# HDSC_HC32M423 register map
Vendor: HDSC Co.,Ltd.; Series: ARMCM4; File version: 1.0
CPU: CM4 r0p1, little endian, MPU, FPU, 4 interrupt priority bits
Registers are 32-bit, read-write, reset 0x0 unless marked. A register's access mark holds for its fields unless they carry their own. Offsets are from the block's base; [hi:lo] are bit positions; {n}, {i} and the like mark numbered series; 'fields as' and 'values as' point back to an identical list.

## GPIO
Base 0x40053800
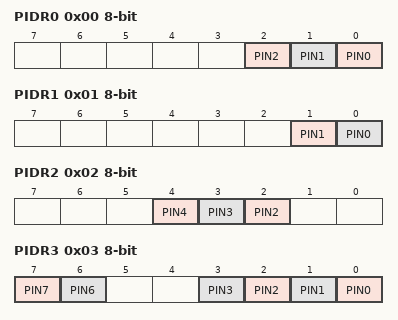
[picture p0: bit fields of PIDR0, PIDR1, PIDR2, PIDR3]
0x00 PIDR0 8-bit ro
  [2] PIN2, [1] PIN1, [0] PIN0
0x01 PIDR1 8-bit ro
  [1] PIN1, [0] PIN0
0x02 PIDR2 8-bit ro
  [4] PIN4, [3] PIN3, [2] PIN2
0x03 PIDR3 8-bit ro
  [7] PIN7, [6] PIN6, [n] PIN{n} (n=0..3)
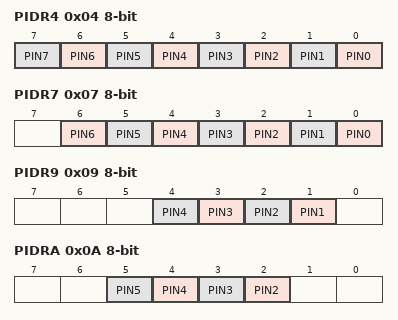
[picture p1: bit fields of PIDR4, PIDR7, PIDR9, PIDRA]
0x04 PIDR4 8-bit ro
  [n] PIN{n} (n=0..7)
0x05 PIDR5 8-bit ro
  [0] PIN0
0x07 PIDR7 8-bit ro
  [n] PIN{n} (n=0..6)
0x09 PIDR9 8-bit ro
  [n] PIN{n} (n=1..4)
0x0A PIDRA 8-bit ro
  [n] PIN{n} (n=2..5)
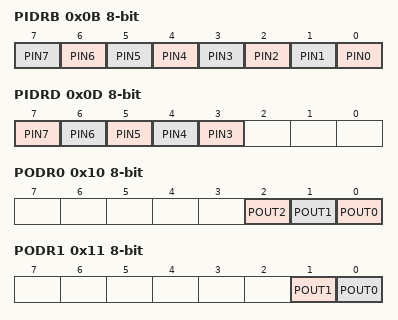
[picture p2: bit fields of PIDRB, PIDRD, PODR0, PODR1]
0x0B PIDRB 8-bit ro
  [n] PIN{n} (n=0..7)
0x0D PIDRD 8-bit ro
  [n] PIN{n} (n=3..7)
0x0E PIDRE 8-bit ro
  [2] PIN2
0x10 PODR0 8-bit
  [2] POUT2, [1] POUT1, [0] POUT0
0x11 PODR1 8-bit
  [1] POUT1, [0] POUT0
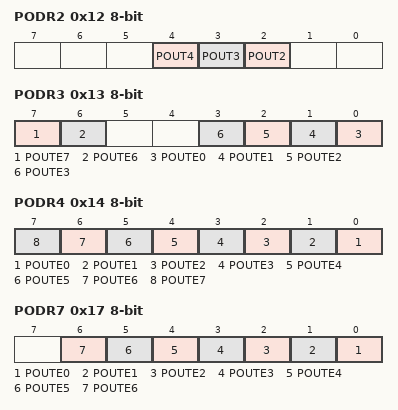
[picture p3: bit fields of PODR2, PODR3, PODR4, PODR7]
0x12 PODR2 8-bit
  [4] POUT4, [3] POUT3, [2] POUT2
0x13 PODR3 8-bit
  [7] POUTE7, [6] POUTE6, [n] POUTE{n} (n=0..3)
0x14 PODR4 8-bit
  [n] POUTE{n} (n=0..7)
0x15 PODR5 8-bit
  [0] POUTE0
0x17 PODR7 8-bit
  [n] POUTE{n} (n=0..6)
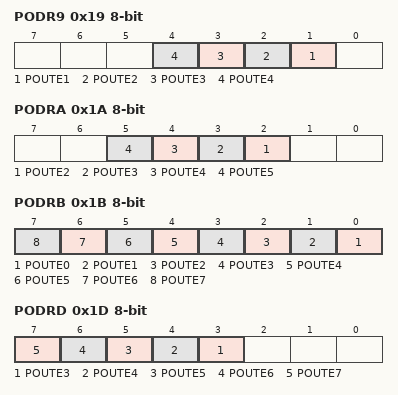
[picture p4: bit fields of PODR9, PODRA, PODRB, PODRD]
0x19 PODR9 8-bit
  [n] POUTE{n} (n=1..4)
0x1A PODRA 8-bit
  [n] POUTE{n} (n=2..5)
0x1B PODRB 8-bit
  [n] POUTE{n} (n=0..7)
0x1D PODRD 8-bit
  [n] POUTE{n} (n=3..7)
0x1E PODRE 8-bit
  [2] POUTE2
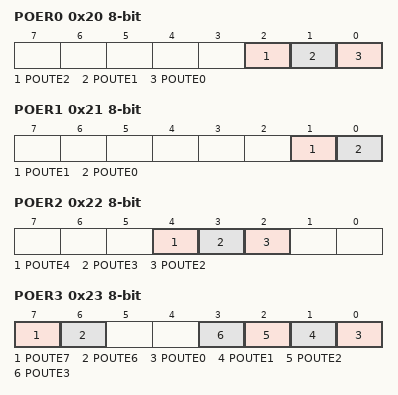
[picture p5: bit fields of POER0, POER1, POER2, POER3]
0x20 POER0 8-bit
  [2] POUTE2, [1] POUTE1, [0] POUTE0
0x21 POER1 8-bit
  [1] POUTE1, [0] POUTE0
0x22 POER2 8-bit
  [4] POUTE4, [3] POUTE3, [2] POUTE2
0x23 POER3 8-bit
  [7] POUTE7, [6] POUTE6, [n] POUTE{n} (n=0..3)
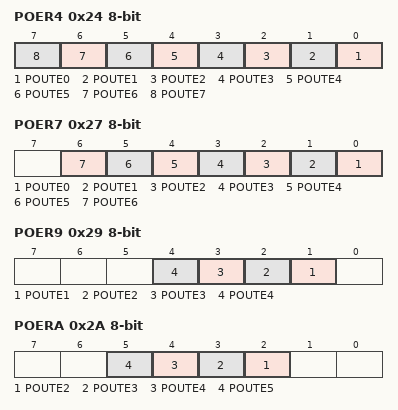
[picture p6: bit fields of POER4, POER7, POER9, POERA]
0x24 POER4 8-bit
  [n] POUTE{n} (n=0..7)
0x25 POER5 8-bit
  [0] POUTE0
0x27 POER7 8-bit
  [n] POUTE{n} (n=0..6)
0x29 POER9 8-bit
  [n] POUTE{n} (n=1..4)
0x2A POERA 8-bit
  [n] POUTE{n} (n=2..5)
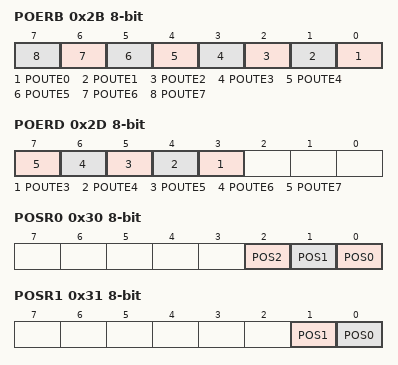
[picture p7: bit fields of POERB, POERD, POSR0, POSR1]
0x2B POERB 8-bit
  [n] POUTE{n} (n=0..7)
0x2D POERD 8-bit
  [n] POUTE{n} (n=3..7)
0x2E POERE 8-bit
  [2] POUTE2
0x30 POSR0 8-bit wo
  [2] POS2, [1] POS1, [0] POS0
0x31 POSR1 8-bit wo
  [1] POS1, [0] POS0
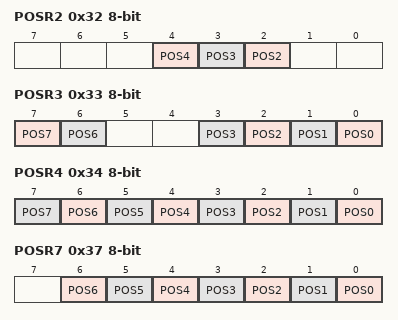
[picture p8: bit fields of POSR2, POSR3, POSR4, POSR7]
0x32 POSR2 8-bit wo
  [4] POS4, [3] POS3, [2] POS2
0x33 POSR3 8-bit wo
  [7] POS7, [6] POS6, [n] POS{n} (n=0..3)
0x34 POSR4 8-bit wo
  [n] POS{n} (n=0..7)
0x35 POSR5 8-bit wo
  [0] POS0
0x37 POSR7 8-bit wo
  [n] POS{n} (n=0..6)
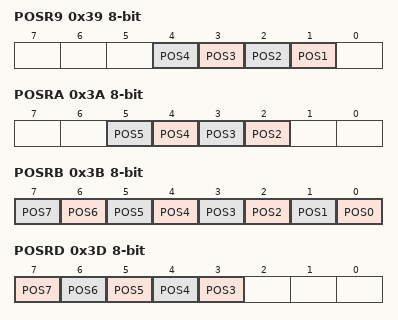
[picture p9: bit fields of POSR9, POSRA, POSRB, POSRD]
0x39 POSR9 8-bit wo
  [n] POS{n} (n=1..4)
0x3A POSRA 8-bit wo
  [n] POS{n} (n=2..5)
0x3B POSRB 8-bit wo
  [n] POS{n} (n=0..7)
0x3D POSRD 8-bit wo
  [n] POS{n} (n=3..7)
0x3E POSRE 8-bit wo
  [2] POS2
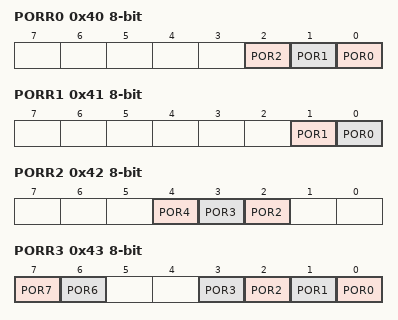
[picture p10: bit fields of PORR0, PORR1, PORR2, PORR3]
0x40 PORR0 8-bit wo
  [2] POR2, [1] POR1, [0] POR0
0x41 PORR1 8-bit wo
  [1] POR1, [0] POR0
0x42 PORR2 8-bit wo
  [4] POR4, [3] POR3, [2] POR2
0x43 PORR3 8-bit wo
  [7] POR7, [6] POR6, [n] POR{n} (n=0..3)
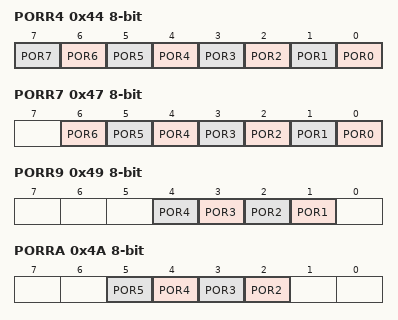
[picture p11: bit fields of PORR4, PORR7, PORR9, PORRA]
0x44 PORR4 8-bit wo
  [n] POR{n} (n=0..7)
0x45 PORR5 8-bit wo
  [0] POR0
0x47 PORR7 8-bit wo
  [n] POR{n} (n=0..6)
0x49 PORR9 8-bit wo
  [n] POR{n} (n=1..4)
0x4A PORRA 8-bit wo
  [n] POR{n} (n=2..5)
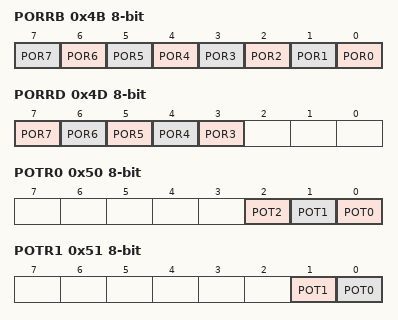
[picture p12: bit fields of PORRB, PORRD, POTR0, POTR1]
0x4B PORRB 8-bit wo
  [n] POR{n} (n=0..7)
0x4D PORRD 8-bit wo
  [n] POR{n} (n=3..7)
0x4E PORRE 8-bit wo
  [2] POR2
0x50 POTR0 8-bit wo
  [2] POT2, [1] POT1, [0] POT0
0x51 POTR1 8-bit wo
  [1] POT1, [0] POT0
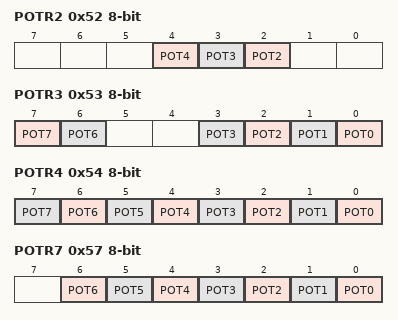
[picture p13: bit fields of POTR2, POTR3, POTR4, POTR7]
0x52 POTR2 8-bit wo
  [4] POT4, [3] POT3, [2] POT2
0x53 POTR3 8-bit wo
  [7] POT7, [6] POT6, [n] POT{n} (n=0..3)
0x54 POTR4 8-bit wo
  [n] POT{n} (n=0..7)
0x55 POTR5 8-bit wo
  [0] POT0
0x57 POTR7 8-bit wo
  [n] POT{n} (n=0..6)
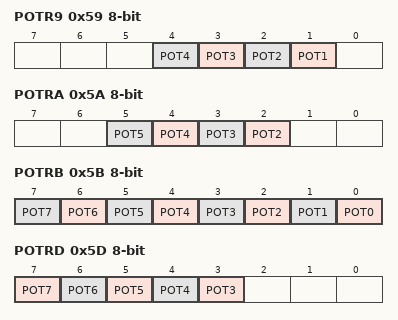
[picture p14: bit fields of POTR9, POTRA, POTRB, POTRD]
0x59 POTR9 8-bit wo
  [n] POT{n} (n=1..4)
0x5A POTRA 8-bit wo
  [n] POT{n} (n=2..5)
0x5B POTRB 8-bit wo
  [n] POT{n} (n=0..7)
0x5D POTRD 8-bit wo
  [n] POT{n} (n=3..7)
0x5E POTRE 8-bit wo
  [2] POT2
0x300 PSPCR 16-bit reset 0x1F
  [4:0] SPFE
0x304 PCCR 16-bit reset 0x4000
  [15:14] RDWT
0x306 PINAER 16-bit
  [14] PINAE14, [13] PINAE13, [11] PINAE11, [10] PINAE10, [9] PINAE9, [7] PINAE7, [n] PINAE{n} (n=0..5)
0x308 PWPR 16-bit
  [15:8] WP wo, [0] WE
{0x400+4i} PCR{i:02} 16-bit (i=0..2)
  [11] INTE, [10] CINSEL, [9] INVE, [8] PIN ro, [6] PUU, [5] LTE, [4] DRV, [2] NOD, [1] POUTE, [0] POUT
{0x402+4i} PFSR{i:02} 16-bit (i=0..2)
  [2:0] FSEL
0x420 PCR10 16-bit
  fields as PCR00
0x422 PFSR10 16-bit
  [2:0] FSEL
0x424 PCR11 16-bit
  fields as PCR00
0x426 PFSR11 16-bit
  [2:0] FSEL
{0x3F0+4i} PCR{i} 16-bit (i=22..24)
  fields as PCR00
{0x3F2+4i} PFSR{i} 16-bit (i=22..24)
  [2:0] FSEL
{0x3E8+4i} PCR{i} 16-bit (i=30..33)
  fields as PCR00
{0x3EA+4i} PFSR{i} 16-bit (i=30..33)
  [2:0] FSEL
0x478 PCR36 16-bit
  [10] CINSEL, [9] INVE, [8] PIN ro, [6] PUU, [5] LTE, [4] DRV, [2] NOD, [1] POUTE, [0] POUT
0x47A PFSR36 16-bit
  [2:0] FSEL
0x47C PCR37 16-bit
  fields as PCR36
0x47E PFSR37 16-bit
  [2:0] FSEL
{0x3E0+4i} PCR{i} 16-bit (i=40..47)
  fields as PCR36
{0x3E2+4i} PFSR{i} 16-bit (i=40..47)
  [2:0] FSEL
0x4A0 PCR50 16-bit
  fields as PCR36
0x4A2 PFSR50 16-bit
  [2:0] FSEL
{0x3C8+4i} PCR{i} 16-bit (i=70..76)
  fields as PCR00
{0x3CA+4i} PFSR{i} 16-bit (i=70..76)
  [2:0] FSEL
{0x3B8+4i} PCR{i} 16-bit (i=91..94)
  fields as PCR00
{0x3BA+4i} PFSR{i} 16-bit (i=91..94)
  [2:0] FSEL
{0x540+4i} PCRA{i} 16-bit (i=2..5)
  fields as PCR00
{0x542+4i} PFSRA{i} 16-bit (i=2..5)
  [2:0] FSEL
{0x560+4i} PCRB{i} 16-bit (i=0..7)
  fields as PCR00
{0x562+4i} PFSRB{i} 16-bit (i=0..7)
  [2:0] FSEL
{0x5A0+4i} PCRD{i} 16-bit (i=3..7)
  fields as PCR00
{0x5A2+4i} PFSRD{i} 16-bit (i=3..7)
  [2:0] FSEL
0x5C8 PCRE2 16-bit
  fields as PCR36
0x5CA PFSRE2 16-bit
  [2:0] FSEL
